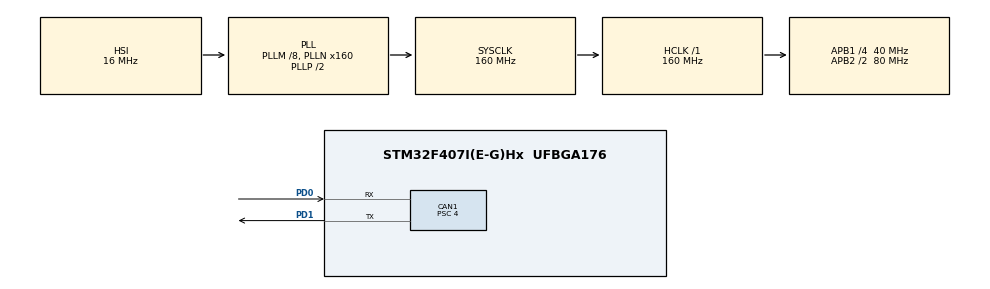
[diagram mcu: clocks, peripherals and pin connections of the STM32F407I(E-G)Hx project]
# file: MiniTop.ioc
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CAN1.BS1=CAN_BS1_8TQ
CAN1.CalculateBaudRate=1000000
CAN1.CalculateTimeBit=1000
CAN1.CalculateTimeQuantum=100.0
CAN1.Prescaler=4
CAN1.SJW=CAN_SJW_1TQ
FREERTOS.Tasks01=CountTask_,0,128,CountTask,As weak,NULL,Dynamic,NULL,NULL;MotorTask_,2,128,MotorTask,As weak,NULL,Dynamic,NULL,NULL
Mcu.Family=STM32F4
Mcu.Name=STM32F407I(E-G)Hx
Mcu.Package=UFBGA176
NVIC.CAN1_RX0_IRQn=true\:5\:0\:false\:false\:true\:true\:true\:true\:true
NVIC.CAN1_RX1_IRQn=true\:5\:0\:false\:false\:true\:true\:true\:true\:true
NVIC.PriorityGroup=NVIC_PRIORITYGROUP_4
PA13.Mode=Serial_Wire
PA13.Signal=SYS_JTMS-SWDIO
PA14.Mode=Serial_Wire
PA14.Signal=SYS_JTCK-SWCLK
PD0.Mode=CAN_Activate
PD0.Signal=CAN1_RX
PD1.Mode=CAN_Activate
PD1.Signal=CAN1_TX
PH0-OSC_IN.Mode=HSE-External-Oscillator
PH0-OSC_IN.Signal=RCC_OSC_IN
PH1-OSC_OUT.Mode=HSE-External-Oscillator
PH1-OSC_OUT.Signal=RCC_OSC_OUT
ProjectManager.HeapSize=0x200
ProjectManager.StackSize=0x400
ProjectManager.TargetToolchain=MDK-ARM V5.32
RCC.48MHZClocksFreq_Value=80000000
RCC.AHBFreq_Value=160000000
RCC.APB1CLKDivider=RCC_HCLK_DIV4
RCC.APB1Freq_Value=40000000
RCC.APB1TimFreq_Value=80000000
RCC.APB2CLKDivider=RCC_HCLK_DIV2
RCC.APB2Freq_Value=80000000
RCC.APB2TimFreq_Value=160000000
RCC.CortexFreq_Value=160000000
RCC.HCLKFreq_Value=160000000
RCC.HSE_VALUE=25000000
RCC.HSI_VALUE=16000000
RCC.LSE_VALUE=32768
RCC.PLLM=8
RCC.PLLN=160
RCC.SYSCLKFreq_VALUE=160000000
RCC.SYSCLKSource=RCC_SYSCLKSOURCE_PLLCLK
RCC.VCOOutputFreq_Value=320000000
VP_FREERTOS_VS_CMSIS_V1.Mode=CMSIS_V1
board=custom

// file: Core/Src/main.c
/* USER CODE BEGIN Header */
/**
  ******************************************************************************
  * @file           : main.c
  * @brief          : Main program body
  ******************************************************************************
  * @attention
  *
  * Copyright (c) 2024 STMicroelectronics.
  * All rights reserved.
  *
  * This software is licensed under terms that can be found in the LICENSE file
  * in the root directory of this software component.
  * If no LICENSE file comes with this software, it is provided AS-IS.
  *
  ******************************************************************************
  */
/* USER CODE END Header */
#include "main.h"
#include "cmsis_os.h"
#include "can.h"
#include "gpio.h"

void SystemClock_Config(void);
void MX_FREERTOS_Init(void);

/* USER CODE BEGIN 0 */

void Can1ChassisMotorFilterConfig()
{
	CAN_FilterTypeDef CAN1_Filter;

	CAN1_Filter.FilterIdHigh         = 0x4020;  //0x201
	CAN1_Filter.FilterIdLow          = 0x4040;  //0x202
	CAN1_Filter.FilterMaskIdHigh     = 0x4060;  //0x203
	CAN1_Filter.FilterMaskIdLow      = 0x4080;  //0x204
	CAN1_Filter.FilterFIFOAssignment = CAN_FILTER_FIFO0;
	CAN1_Filter.FilterBank           = 0;
	CAN1_Filter.FilterMode           = CAN_FILTERMODE_IDLIST;
	CAN1_Filter.FilterScale          = CAN_FILTERSCALE_16BIT;
	CAN1_Filter.FilterActivation     = ENABLE;

	if(HAL_CAN_ConfigFilter(&hcan1,&CAN1_Filter) != HAL_OK)
	{
		Error_Handler();
	}
}
/* USER CODE END 0 */

int main(void)
{

  /* MCU Configuration--------------------------------------------------------*/

  /* Reset of all peripherals, Initializes the Flash interface and the Systick. */
  HAL_Init();

  /* Configure the system clock */
  SystemClock_Config();

  /* Initialize all configured peripherals */
  MX_GPIO_Init();
  MX_CAN1_Init();
  /* USER CODE BEGIN 2 */
	Can1ChassisMotorFilterConfig();
	HAL_CAN_ActivateNotification(&hcan1,CAN_IT_RX_FIFO0_MSG_PENDING);
	HAL_CAN_Start(&hcan1);
  /* USER CODE END 2 */

  /* Call init function for freertos objects (in cmsis_os2.c) */
  MX_FREERTOS_Init();

  /* Start scheduler */
  osKernelStart();

  /* We should never get here as control is now taken by the scheduler */

  /* Infinite loop */
  while (1)
  {

  }
}

void SystemClock_Config(void)
{
  RCC_OscInitTypeDef RCC_OscInitStruct = {0};
  RCC_ClkInitTypeDef RCC_ClkInitStruct = {0};

  /** Configure the main internal regulator output voltage
  */
  __HAL_RCC_PWR_CLK_ENABLE();
  __HAL_PWR_VOLTAGESCALING_CONFIG(PWR_REGULATOR_VOLTAGE_SCALE1);

  /** Initializes the RCC Oscillators according to the specified parameters
  * in the RCC_OscInitTypeDef structure.
  */
  RCC_OscInitStruct.OscillatorType = RCC_OSCILLATORTYPE_HSI;
  RCC_OscInitStruct.HSIState = RCC_HSI_ON;
  RCC_OscInitStruct.HSICalibrationValue = RCC_HSICALIBRATION_DEFAULT;
  RCC_OscInitStruct.PLL.PLLState = RCC_PLL_ON;
  RCC_OscInitStruct.PLL.PLLSource = RCC_PLLSOURCE_HSI;
  RCC_OscInitStruct.PLL.PLLM = 8;
  RCC_OscInitStruct.PLL.PLLN = 160;
  RCC_OscInitStruct.PLL.PLLP = RCC_PLLP_DIV2;
  RCC_OscInitStruct.PLL.PLLQ = 4;
  if (HAL_RCC_OscConfig(&RCC_OscInitStruct) != HAL_OK)
  {
    Error_Handler();
  }

  /** Initializes the CPU, AHB and APB buses clocks
  */
  RCC_ClkInitStruct.ClockType = RCC_CLOCKTYPE_HCLK|RCC_CLOCKTYPE_SYSCLK
                              |RCC_CLOCKTYPE_PCLK1|RCC_CLOCKTYPE_PCLK2;
  RCC_ClkInitStruct.SYSCLKSource = RCC_SYSCLKSOURCE_PLLCLK;
  RCC_ClkInitStruct.AHBCLKDivider = RCC_SYSCLK_DIV1;
  RCC_ClkInitStruct.APB1CLKDivider = RCC_HCLK_DIV4;
  RCC_ClkInitStruct.APB2CLKDivider = RCC_HCLK_DIV2;

  if (HAL_RCC_ClockConfig(&RCC_ClkInitStruct, FLASH_LATENCY_5) != HAL_OK)
  {
    Error_Handler();
  }
}

void Error_Handler(void)
{
  __disable_irq();
  while (1)
  {
  }
}

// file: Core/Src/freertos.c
/* USER CODE BEGIN Header */
/**
  ******************************************************************************
  * File Name          : freertos.c
  * Description        : Code for freertos applications
  ******************************************************************************
  * @attention
  *
  * Copyright (c) 2024 STMicroelectronics.
  * All rights reserved.
  *
  * This software is licensed under terms that can be found in the LICENSE file
  * in the root directory of this software component.
  * If no LICENSE file comes with this software, it is provided AS-IS.
  *
  ******************************************************************************
  */
/* USER CODE END Header */

#include "FreeRTOS.h"
#include "task.h"
#include "main.h"
#include "cmsis_os.h"

osThreadId CountTask_Handle;
osThreadId MotorTask_Handle;

void CountTask(void const * argument);
void MotorTask(void const * argument);

void MX_FREERTOS_Init(void); /* (MISRA C 2004 rule 8.1) */

/* GetIdleTaskMemory prototype (linked to static allocation support) */
void vApplicationGetIdleTaskMemory( StaticTask_t **ppxIdleTaskTCBBuffer, StackType_t **ppxIdleTaskStackBuffer, uint32_t *pulIdleTaskStackSize );

/* USER CODE BEGIN GET_IDLE_TASK_MEMORY */
static StaticTask_t xIdleTaskTCBBuffer;
static StackType_t xIdleStack[configMINIMAL_STACK_SIZE];

void vApplicationGetIdleTaskMemory( StaticTask_t **ppxIdleTaskTCBBuffer, StackType_t **ppxIdleTaskStackBuffer, uint32_t *pulIdleTaskStackSize )
{
  *ppxIdleTaskTCBBuffer = &xIdleTaskTCBBuffer;
  *ppxIdleTaskStackBuffer = &xIdleStack[0];
  *pulIdleTaskStackSize = configMINIMAL_STACK_SIZE;
  /* place for user code */
}
/* USER CODE END GET_IDLE_TASK_MEMORY */

void MX_FREERTOS_Init(void) {

  /* Create the thread(s) */
  /* definition and creation of CountTask_ */
  osThreadDef(CountTask_, CountTask, osPriorityNormal, 0, 128);
  CountTask_Handle = osThreadCreate(osThread(CountTask_), NULL);

  /* definition and creation of MotorTask_ */
  osThreadDef(MotorTask_, MotorTask, osPriorityHigh, 0, 128);
  MotorTask_Handle = osThreadCreate(osThread(MotorTask_), NULL);

}

__weak void CountTask(void const * argument)
{
  for(;;)
  {
    osDelay(1);
  }
}

__weak void MotorTask(void const * argument)
{
  for(;;)
  {
    osDelay(1);
  }
}
